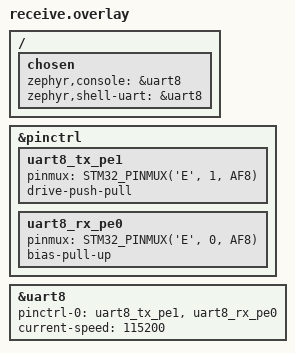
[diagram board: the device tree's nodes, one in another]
/* UART8 沿用本轮无线串口接线，PE1 发、PE0 收。 */
/ {
    chosen {
        zephyr,console = &uart8;
        zephyr,shell-uart = &uart8;
    };
};

&pinctrl {
    uart8_tx_pe1: uart8_tx_pe1 {
        pinmux = <STM32_PINMUX('E', 1, AF8)>;
        drive-push-pull;
    };
    uart8_rx_pe0: uart8_rx_pe0 {
        pinmux = <STM32_PINMUX('E', 0, AF8)>;
        bias-pull-up;
    };
};

&uart8 {
    pinctrl-0 = <&uart8_tx_pe1 &uart8_rx_pe0>;
    pinctrl-names = "default";
    current-speed = <115200>;
    status = "okay";
};
